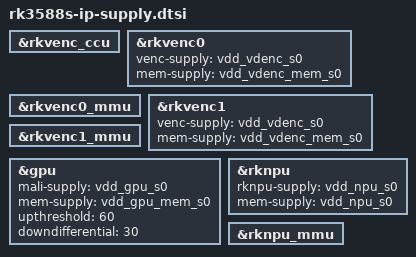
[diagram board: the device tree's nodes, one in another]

&rkvenc_ccu {
	status = "okay";
};

&rkvenc0 {
	venc-supply = <&vdd_vdenc_s0>;
	mem-supply = <&vdd_vdenc_mem_s0>;
	status = "okay";
};

&rkvenc0_mmu {
	status = "okay";
};

&rkvenc1 {
	venc-supply = <&vdd_vdenc_s0>;
	mem-supply = <&vdd_vdenc_mem_s0>;
	status = "okay";
};

&rkvenc1_mmu {
	status = "okay";
};

&gpu {
	mali-supply = <&vdd_gpu_s0>;
	mem-supply = <&vdd_gpu_mem_s0>;
	upthreshold = <60>;
	downdifferential = <30>;
	status = "okay";
};

&rknpu {
	rknpu-supply = <&vdd_npu_s0>;
	mem-supply = <&vdd_npu_s0>;
	status = "okay";
};

&rknpu_mmu {
	status = "okay";
};
